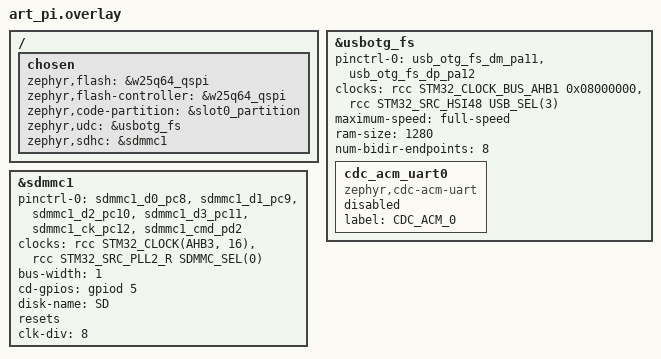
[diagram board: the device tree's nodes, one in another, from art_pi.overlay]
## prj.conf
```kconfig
CONFIG_DISK_ACCESS=y
CONFIG_LOG=y
CONFIG_FILE_SYSTEM=y
CONFIG_FAT_FILESYSTEM_ELM=y
CONFIG_PRINTK=y



CONFIG_FILE_SYSTEM_MKFS=y
# #------------fatfs----------------
CONFIG_FS_FATFS_MKFS=y    


# #------------ext2----------------------
CONFIG_FILE_SYSTEM_EXT2=y
CONFIG_TEST_RANDOM_GENERATOR=y
#ext2 的 mkfs 会用到比较深的调用栈/临时缓冲。建议把主线程栈增大到 8 KiB 起步
CONFIG_MAIN_STACK_SIZE=8192
#（可选，若在工作队列里做过 FS 操作，再给它加大）
CONFIG_SYSTEM_WORKQUEUE_STACK_SIZE=4096


# USB 设备栈 + MSC 类
CONFIG_USB_DEVICE_STACK=y
# 打开 MSC 类（具体 Kconfig 名称在不同版本略有差异，建议 menuconfig 里搜索 “Mass storage class / MSC” 勾选）
CONFIG_USB_MASS_STORAGE=y

# 让 MSC 使用哪块“disk_access”设备（与 disk-name 对应）
CONFIG_MASS_STORAGE_DISK_NAME="SD"

# SDMMC 磁盘驱动
CONFIG_DISK_DRIVER_SDMMC=y


#此处必须加上。默认会开启，使用HSI48作为时钟源，stm32h7不支持该时钟，会导致初始化失败
CONFIG_SDMMC_STM32_CLOCK_CHECK=n
```

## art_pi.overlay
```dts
/*
 * Copyright (c) 2025 STMicroelectronics
 *
 * SPDX-License-Identifier: Apache-2.0
 */

/*
 * Define the device, controller and partition to be the external memory
 * for running the application in external NOR from MCUboot
 */
/ {
	chosen {
		zephyr,flash = &w25q64_qspi;
		zephyr,flash-controller = &w25q64_qspi;
		zephyr,code-partition = &slot0_partition;
        zephyr,udc = &usbotg_fs;
		zephyr,sdhc = &sdmmc1;
	};
};

zephyr_udc0: &usbotg_fs {
	pinctrl-0 = <&usb_otg_fs_dm_pa11 &usb_otg_fs_dp_pa12>;
	pinctrl-names = "default";

	clocks = <&rcc STM32_CLOCK_BUS_AHB1 0x08000000>,
		 <&rcc STM32_SRC_HSI48 USB_SEL(3)>;

	maximum-speed = "full-speed";
	ram-size = <1280>;
	num-bidir-endpoints = <8>;

	status = "okay";

	cdc_acm_uart0: cdc_acm_uart0 {
		compatible = "zephyr,cdc-acm-uart";
		label = "CDC_ACM_0";
        status = "disabled";
	};
};




&sdmmc1 {
	status = "okay";
	pinctrl-names = "default";
	pinctrl-0 = <
	&sdmmc1_d0_pc8
	&sdmmc1_d1_pc9
	&sdmmc1_d2_pc10
	&sdmmc1_d3_pc11
	&sdmmc1_ck_pc12
	&sdmmc1_cmd_pd2
	>;

	clocks = <&rcc STM32_CLOCK(AHB3, 16)>,
	     <&rcc STM32_SRC_PLL2_R SDMMC_SEL(0)>;

	bus-width = <1>;
	cd-gpios = <&gpiod 5 (GPIO_PULL_UP|GPIO_ACTIVE_HIGH)>;
	disk-name = "SD";
	resets;
	reset-names = "sdmmc1_reset";

	clk-div = <8>;
};
```

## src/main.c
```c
#include <zephyr/kernel.h>
#include <zephyr/device.h>
#include <zephyr/storage/disk_access.h>
#include <zephyr/logging/log.h>
#include <zephyr/fs/fs.h>
#include <ff.h>



int main(void)
{
   int rc;

    rc = disk_access_init("SD");
    printk("disk_access_init rc=%d\n", rc);

#ifdef CONFIG_FILE_SYSTEM_MKFS
    // /* 一次性在裸盘上创建 FAT（不挂载，直接指定设备名） */
    // rc = fs_mkfs(FS_FATFS, (uintptr_t)"SD", NULL, 0);
    // printk("fs_mkfs(FAT,RAM) rc=%d\n", rc);
#endif

    rc = usb_enable(NULL);
    printk("usb_enable rc=%d\n", rc);

	while (1) {
		k_sleep(K_MSEC(1000));
	}
	return 0;
}
```
